# STM32U5A5xx register map
File version: 1.0
Registers are 32-bit, read-write, reset 0x0 unless marked. A register's access mark holds for its fields unless they carry their own. Offsets are from the block's base; [hi:lo] are bit positions; {n}, {i} and the like mark numbered series; 'fields as' and 'values as' point back to an identical list.

## RTC — Real-Time Clock
Base 0x46007800
Same registers: RTC_S 0x56007800
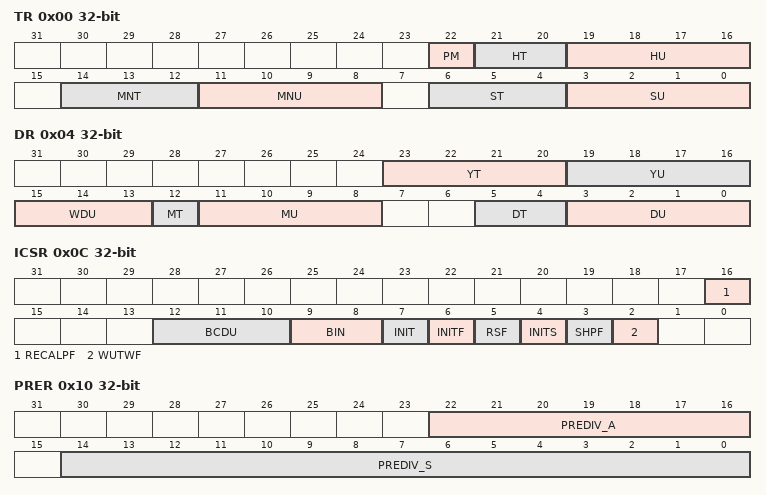
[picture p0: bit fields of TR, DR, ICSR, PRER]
0x00 TR — RTC time register
  [22] PM
    0=AM_OR_24 (AM or 24-hour format); 1=PM
  [21:20] HT
  [19:16] HU
  [14:12] MNT
  [11:8] MNU
  [6:4] ST
  [3:0] SU
0x04 DR — RTC date register
  [23:20] YT, [19:16] YU, [15:13] WDU, [12] MT, [11:8] MU, [5:4] DT, [3:0] DU
0x08 SSR — RTC sub second register
  [31:0] SS
0x0C ICSR — RTC initialization control and status register
  [16] RECALPF
  [12:10] BCDU
    {v}=1s calendar increment is generated each time SS[{v+7}:0] = 0 (v=0..7)
  [9:8] BIN
    0=NONE (Free running BCD calendar mode (Binary mode disabled).); 1=ONLY (Free running Binary mode (BCD mode disabled)); 2=MIX (Free running BCD calendar and Binary mode enable)
  [7] INIT
  [6] INITF
  [5] RSF
  [4] INITS
  [3] SHPF
  [2] WUTWF
0x10 PRER — RTC prescaler register
  [22:16] PREDIV_A, [14:0] PREDIV_S
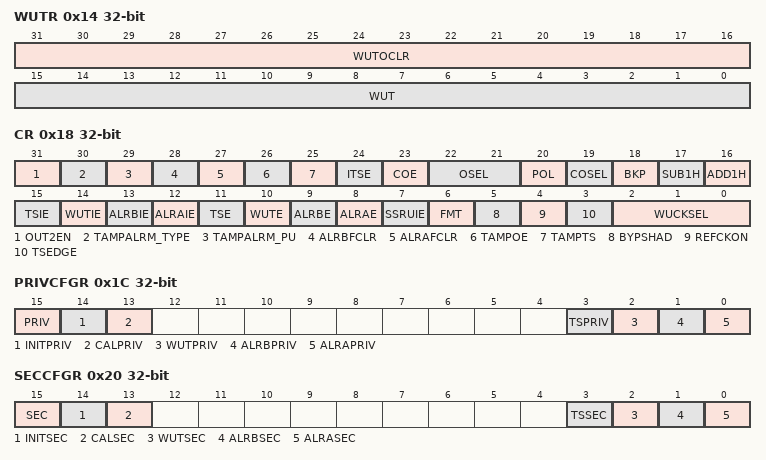
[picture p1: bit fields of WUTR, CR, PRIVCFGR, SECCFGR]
0x14 WUTR — RTC wakeup timer register
  [31:16] WUTOCLR, [15:0] WUT
0x18 CR — RTC control register
  [31] OUT2EN — RTC_OUT2 output enable
  [30] TAMPALRM_TYPE — TAMPALARM output type
    1=OPENDRAIN (RTC_ALARM is open-drain output); 0=PUSHPULL (RTC_ALARM is push-pull output)
  [29] TAMPALRM_PU — TAMPALARM output pull-up config
  [28] ALRBFCLR — Alarm B mask
  [27] ALRAFCLR — Alarm A mask
  [26] TAMPOE — Tamper detection output enable on TAMPALARM
  [25] TAMPTS — Activate timestamp on tamper detection event
  [24] ITSE — Timestamp on internal event enable
  [23] COE
  [22:21] OSEL
    0=DISABLE (Output disabled); 1=ALMA (Alarm A output enabled); 2=ALMB (Alarm B output enabled); 3=WAKEUP (Wakeup output enabled)
  [20] POL
    0=HIGH (Pin is high when ALRAF/ALRBF/WUTF is asserted (depending on OSEL)); 1=LOW (Pin is low when ALRAF/ALRBF/WUTF is asserted (depending on OSEL))
  [19] COSEL
  [18] BKP
  [17] SUB1H
  [16] ADD1H
  [15] TSIE
  [14] WUTIE
  [13] ALRBIE
  [12] ALRAIE
  [11] TSE
  [10] WUTE
  [9] ALRBE
  [8] ALRAE
  [7] SSRUIE
  [6] FMT
    0=HOURFORMAT_24HOUR (24 hour/day format); 1=AMPM (AM/PM hour format)
  [5] BYPSHAD
  [4] REFCKON
  [3] TSEDGE
    0=RISING (RTC_TS input rising edge generates a time-stamp event); 1=FALLING (RTC_TS input falling edge generates a time-stamp even)
  [2:0] WUCKSEL
    0=DIV_16 (RTC/16 clock is selected); 1=DIV_8 (RTC/8 clock is selected); 2=DIV_4 (RTC/4 clock is selected); 3=DIV_2 (RTC/2 clock is selected); 4=CKSPRE (ck_spre (usually 1 Hz) clock is selected); 6=CKSPRE_WUT (ck_spre (usually 1 Hz) clock is selected and 2exp16 is added to the WUT counter value)
0x1C PRIVCFGR — RTC privilege mode control register
  [15] PRIV, [14] INITPRIV, [13] CALPRIV, [3] TSPRIV, [2] WUTPRIV, [1] ALRBPRIV, [0] ALRAPRIV
0x20 SECCFGR — RTC secure mode control register
  [15] SEC, [14] INITSEC, [13] CALSEC, [3] TSSEC, [2] WUTSEC, [1] ALRBSEC, [0] ALRASEC
0x24 WPR — RTC write protection register
  [7:0] KEY
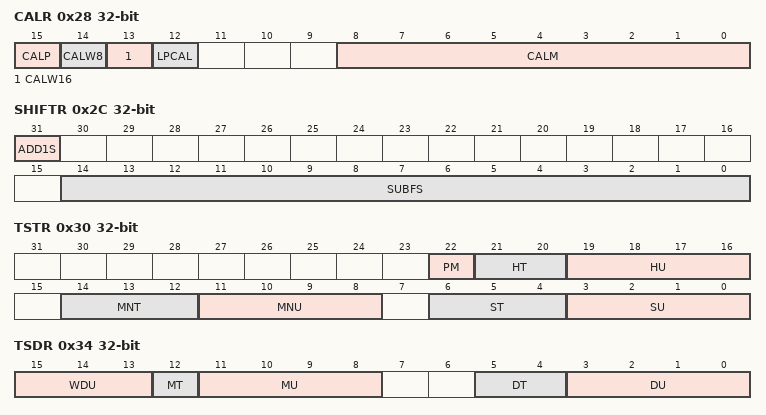
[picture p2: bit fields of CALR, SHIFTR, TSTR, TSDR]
0x28 CALR — RTC calibration register
  [15] CALP
    0=NONE (No RTCCLK pulses are added); 1=SET (One RTCCLK pulse is effectively inserted every 2exp11 pulses (frequency increased by 488.5 ppm))
  [14] CALW8
  [13] CALW16
  [12] LPCAL
  [8:0] CALM
0x2C SHIFTR — RTC shift control register
  [31] ADD1S, [14:0] SUBFS
0x30 TSTR — RTC time stamp time register
  [22] PM
    0=AM (AM or 24-hour format); 1=PM
  [21:20] HT
  [19:16] HU
  [14:12] MNT
  [11:8] MNU
  [6:4] ST
  [3:0] SU
0x34 TSDR — RTC time stamp date register
  [15:13] WDU, [12] MT, [11:8] MU, [5:4] DT, [3:0] DU
0x38 TSSSR — RTC time-stamp sub second register
  [31:0] SS — rtc timestamp sub second >
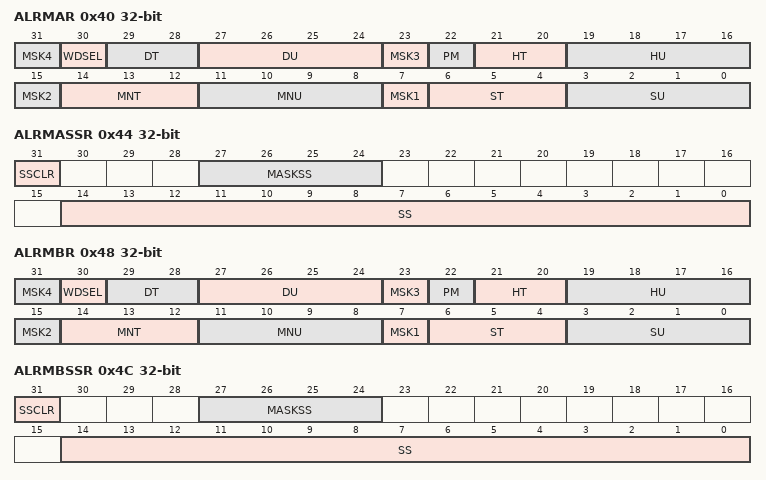
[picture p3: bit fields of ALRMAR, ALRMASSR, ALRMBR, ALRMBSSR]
0x40 ALRMAR — RTC alarm A register
  [8n-1] MSK{n} (n=1..4)
  [30] WDSEL
  [29:28] DT
  [27:24] DU
  [22] PM
    0=AM (AM or 24-hour format); 1=PM
  [21:20] HT
  [19:16] HU
  [14:12] MNT
  [11:8] MNU
  [6:4] ST
  [3:0] SU
0x44 ALRMASSR — RTC alarm A sub second register
  [31] SSCLR
    0=NO (The synchronous binary counter (SS[31:0] in RTC_SSR) is free-running.); 1=YES (The synchronous binary counter (SS[31:0] in RTC_SSR) is running from 0xFFFF FFFF to RTC_ALRMABINR -> SS[31:0] value and is automatically reloaded with 0xFFFF FFFF when reaching RTC_ALRMABINR -> SS[31:0].)
  [27:24] MASKSS
  [14:0] SS
0x48 ALRMBR — RTC alarm B register
  fields as ALRMAR
0x4C ALRMBSSR — RTC alarm B sub second register
  fields as ALRMASSR
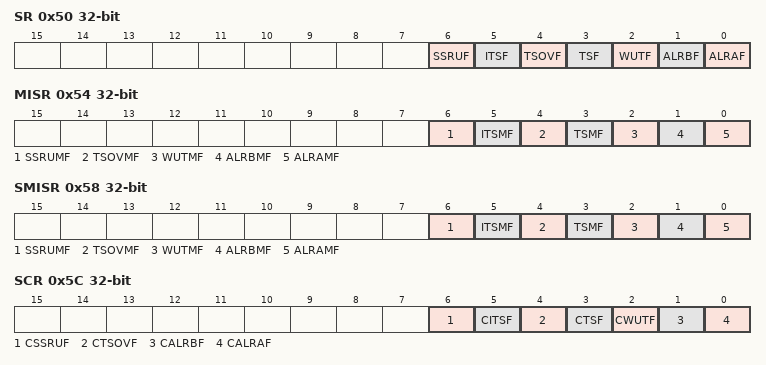
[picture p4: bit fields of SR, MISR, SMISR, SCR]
0x50 SR — RTC Status register
  [6] SSRUF, [5] ITSF, [4] TSOVF, [3] TSF, [2] WUTF, [1] ALRBF, [0] ALRAF
0x54 MISR — RTC masked interrupt status register
  [6] SSRUMF, [5] ITSMF, [4] TSOVMF, [3] TSMF, [2] WUTMF, [1] ALRBMF, [0] ALRAMF
0x58 SMISR — RTC secure masked interrupt status register
  fields as MISR
0x5C SCR — RTC status Clear register
  [6] CSSRUF, [5] CITSF, [4] CTSOVF, [3] CTSF, [2] CWUTF, [1] CALRBF, [0] CALRAF
0x70 ALRABINR — RTC alarm A binary mode register
  [31:0] SS
0x74 ALRBBINR — RTC alarm B binary mode register
  [31:0] SS
